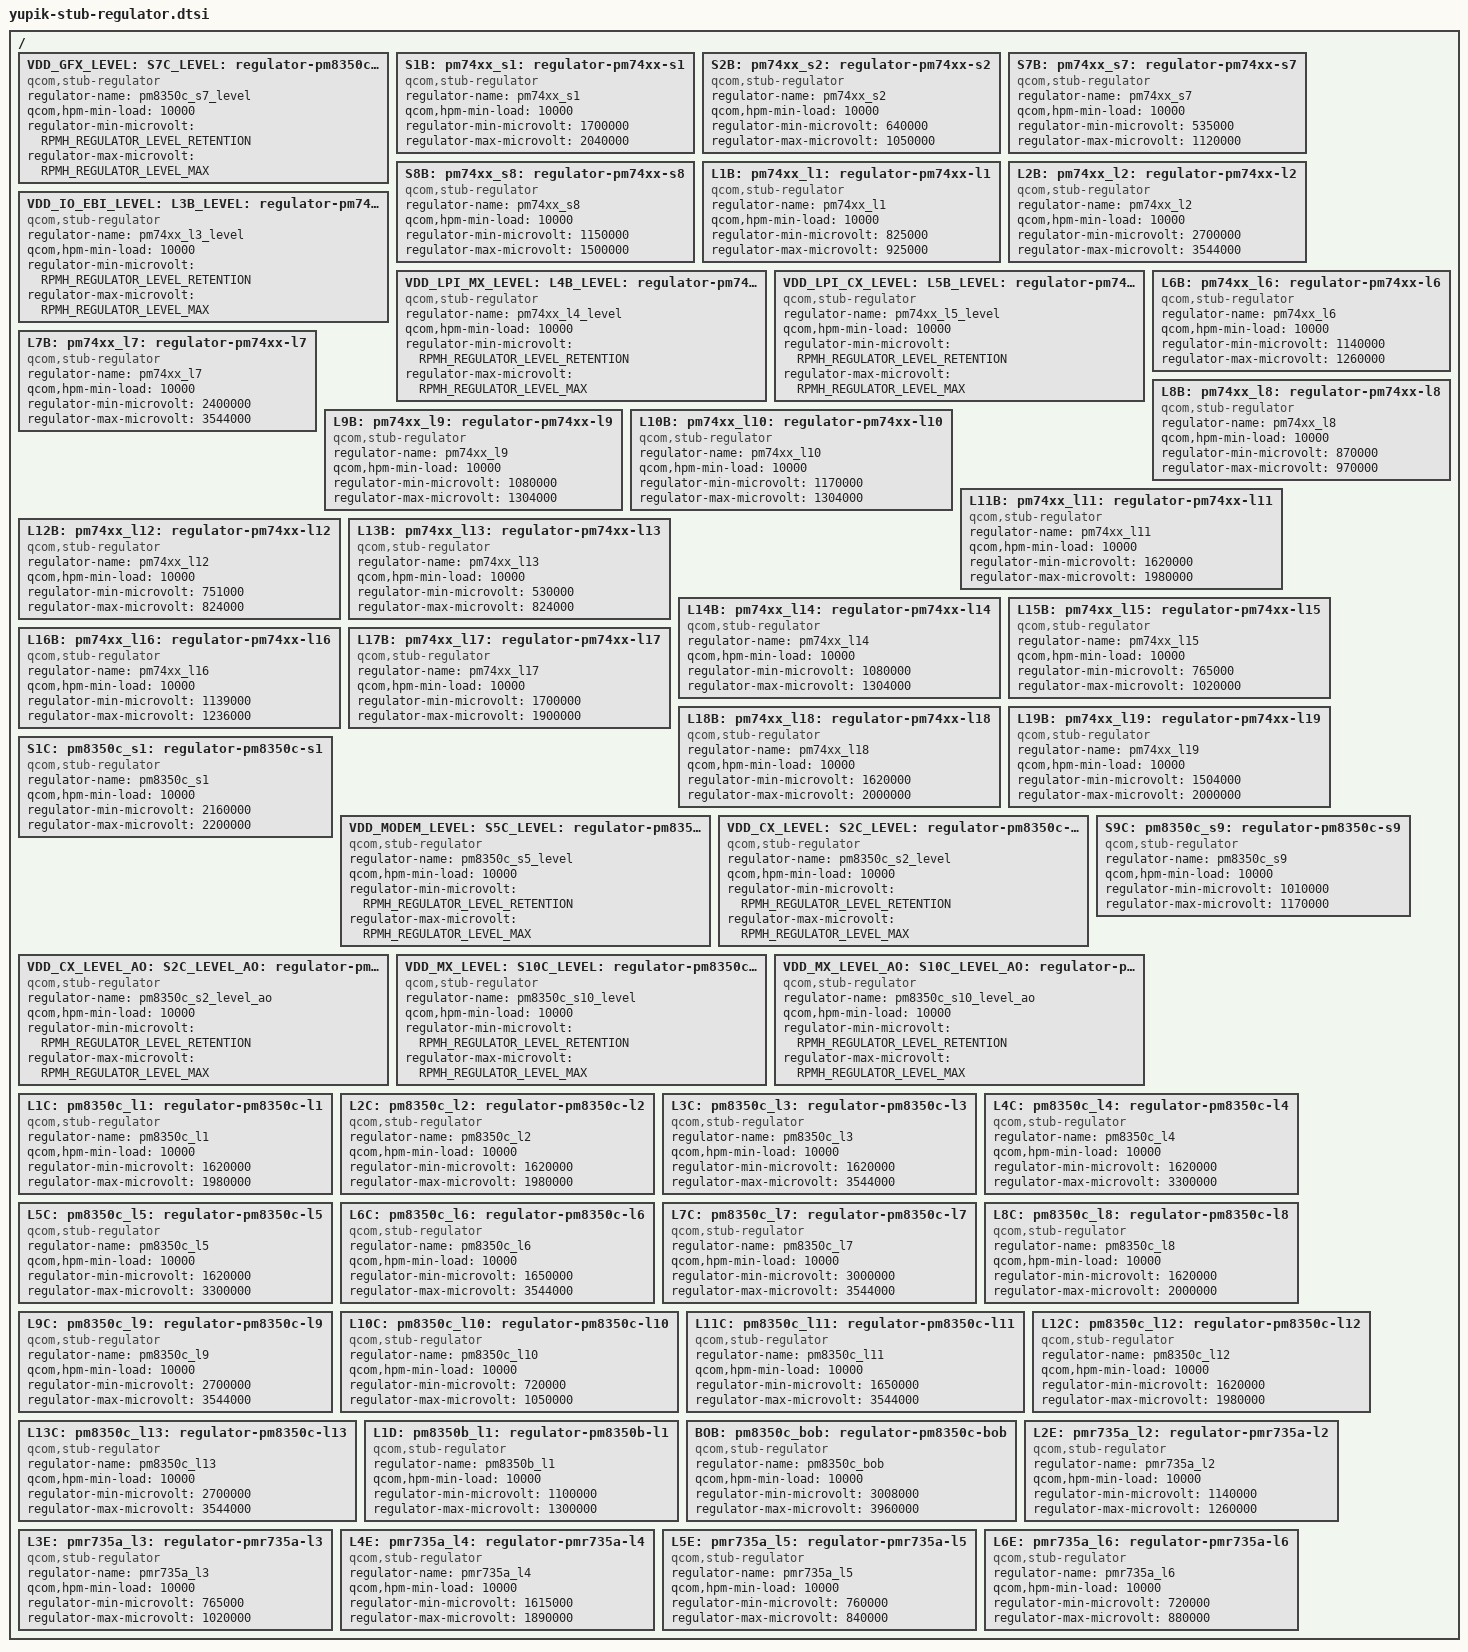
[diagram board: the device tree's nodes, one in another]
#include <dt-bindings/regulator/qcom,rpmh-regulator-levels.h>

/ {
	VDD_GFX_LEVEL:
	S7C_LEVEL:
	pm8350c_s7_level: regulator-pm8350c-s7-level {
		compatible = "qcom,stub-regulator";
		regulator-name = "pm8350c_s7_level";
		qcom,hpm-min-load = <10000>;
		regulator-min-microvolt = <RPMH_REGULATOR_LEVEL_RETENTION>;
		regulator-max-microvolt = <RPMH_REGULATOR_LEVEL_MAX>;
	};

	S1B:
	pm74xx_s1: regulator-pm74xx-s1 {
		compatible = "qcom,stub-regulator";
		regulator-name = "pm74xx_s1";
		qcom,hpm-min-load = <10000>;
		regulator-min-microvolt = <1700000>;
		regulator-max-microvolt = <2040000>;
	};

	S2B:
	pm74xx_s2: regulator-pm74xx-s2 {
		compatible = "qcom,stub-regulator";
		regulator-name = "pm74xx_s2";
		qcom,hpm-min-load = <10000>;
		regulator-min-microvolt = <640000>;
		regulator-max-microvolt = <1050000>;
	};

	S7B:
	pm74xx_s7: regulator-pm74xx-s7 {
		compatible = "qcom,stub-regulator";
		regulator-name = "pm74xx_s7";
		qcom,hpm-min-load = <10000>;
		regulator-min-microvolt = <535000>;
		regulator-max-microvolt = <1120000>;
	};

	S8B:
	pm74xx_s8: regulator-pm74xx-s8 {
		compatible = "qcom,stub-regulator";
		regulator-name = "pm74xx_s8";
		qcom,hpm-min-load = <10000>;
		regulator-min-microvolt = <1150000>;
		regulator-max-microvolt = <1500000>;
	};

	L1B:
	pm74xx_l1: regulator-pm74xx-l1 {
		compatible = "qcom,stub-regulator";
		regulator-name = "pm74xx_l1";
		qcom,hpm-min-load = <10000>;
		regulator-min-microvolt = <825000>;
		regulator-max-microvolt = <925000>;
	};

	L2B:
	pm74xx_l2: regulator-pm74xx-l2 {
		compatible = "qcom,stub-regulator";
		regulator-name = "pm74xx_l2";
		qcom,hpm-min-load = <10000>;
		regulator-min-microvolt = <2700000>;
		regulator-max-microvolt = <3544000>;
	};

	VDD_IO_EBI_LEVEL:
	L3B_LEVEL:
	pm74xx_l3_level: regulator-pm74xx-l3-level {
		compatible = "qcom,stub-regulator";
		regulator-name = "pm74xx_l3_level";
		qcom,hpm-min-load = <10000>;
		regulator-min-microvolt = <RPMH_REGULATOR_LEVEL_RETENTION>;
		regulator-max-microvolt = <RPMH_REGULATOR_LEVEL_MAX>;
	};

	VDD_LPI_MX_LEVEL:
	L4B_LEVEL:
	pm74xx_l4_level: regulator-pm74xx-l4-level {
		compatible = "qcom,stub-regulator";
		regulator-name = "pm74xx_l4_level";
		qcom,hpm-min-load = <10000>;
		regulator-min-microvolt = <RPMH_REGULATOR_LEVEL_RETENTION>;
		regulator-max-microvolt = <RPMH_REGULATOR_LEVEL_MAX>;
	};

	VDD_LPI_CX_LEVEL:
	L5B_LEVEL:
	pm74xx_l5_level: regulator-pm74xx-l5-level {
		compatible = "qcom,stub-regulator";
		regulator-name = "pm74xx_l5_level";
		qcom,hpm-min-load = <10000>;
		regulator-min-microvolt = <RPMH_REGULATOR_LEVEL_RETENTION>;
		regulator-max-microvolt = <RPMH_REGULATOR_LEVEL_MAX>;
	};

	L6B:
	pm74xx_l6: regulator-pm74xx-l6 {
		compatible = "qcom,stub-regulator";
		regulator-name = "pm74xx_l6";
		qcom,hpm-min-load = <10000>;
		regulator-min-microvolt = <1140000>;
		regulator-max-microvolt = <1260000>;
	};

	L7B:
	pm74xx_l7: regulator-pm74xx-l7 {
		compatible = "qcom,stub-regulator";
		regulator-name = "pm74xx_l7";
		qcom,hpm-min-load = <10000>;
		regulator-min-microvolt = <2400000>;
		regulator-max-microvolt = <3544000>;
	};

	L8B:
	pm74xx_l8: regulator-pm74xx-l8 {
		compatible = "qcom,stub-regulator";
		regulator-name = "pm74xx_l8";
		qcom,hpm-min-load = <10000>;
		regulator-min-microvolt = <870000>;
		regulator-max-microvolt = <970000>;
	};

	L9B:
	pm74xx_l9: regulator-pm74xx-l9 {
		compatible = "qcom,stub-regulator";
		regulator-name = "pm74xx_l9";
		qcom,hpm-min-load = <10000>;
		regulator-min-microvolt = <1080000>;
		regulator-max-microvolt = <1304000>;
	};

	L10B:
	pm74xx_l10: regulator-pm74xx-l10 {
		compatible = "qcom,stub-regulator";
		regulator-name = "pm74xx_l10";
		qcom,hpm-min-load = <10000>;
		regulator-min-microvolt = <1170000>;
		regulator-max-microvolt = <1304000>;
	};

	L11B:
	pm74xx_l11: regulator-pm74xx-l11 {
		compatible = "qcom,stub-regulator";
		regulator-name = "pm74xx_l11";
		qcom,hpm-min-load = <10000>;
		regulator-min-microvolt = <1620000>;
		regulator-max-microvolt = <1980000>;
	};

	L12B:
	pm74xx_l12: regulator-pm74xx-l12 {
		compatible = "qcom,stub-regulator";
		regulator-name = "pm74xx_l12";
		qcom,hpm-min-load = <10000>;
		regulator-min-microvolt = <751000>;
		regulator-max-microvolt = <824000>;
	};

	L13B:
	pm74xx_l13: regulator-pm74xx-l13 {
		compatible = "qcom,stub-regulator";
		regulator-name = "pm74xx_l13";
		qcom,hpm-min-load = <10000>;
		regulator-min-microvolt = <530000>;
		regulator-max-microvolt = <824000>;
	};

	L14B:
	pm74xx_l14: regulator-pm74xx-l14 {
		compatible = "qcom,stub-regulator";
		regulator-name = "pm74xx_l14";
		qcom,hpm-min-load = <10000>;
		regulator-min-microvolt = <1080000>;
		regulator-max-microvolt = <1304000>;
	};

	L15B:
	pm74xx_l15: regulator-pm74xx-l15 {
		compatible = "qcom,stub-regulator";
		regulator-name = "pm74xx_l15";
		qcom,hpm-min-load = <10000>;
		regulator-min-microvolt = <765000>;
		regulator-max-microvolt = <1020000>;
	};

	L16B:
	pm74xx_l16: regulator-pm74xx-l16 {
		compatible = "qcom,stub-regulator";
		regulator-name = "pm74xx_l16";
		qcom,hpm-min-load = <10000>;
		regulator-min-microvolt = <1139000>;
		regulator-max-microvolt = <1236000>;
	};

	L17B:
	pm74xx_l17: regulator-pm74xx-l17 {
		compatible = "qcom,stub-regulator";
		regulator-name = "pm74xx_l17";
		qcom,hpm-min-load = <10000>;
		regulator-min-microvolt = <1700000>;
		regulator-max-microvolt = <1900000>;
	};

	L18B:
	pm74xx_l18: regulator-pm74xx-l18 {
		compatible = "qcom,stub-regulator";
		regulator-name = "pm74xx_l18";
		qcom,hpm-min-load = <10000>;
		regulator-min-microvolt = <1620000>;
		regulator-max-microvolt = <2000000>;
	};

	L19B:
	pm74xx_l19: regulator-pm74xx-l19 {
		compatible = "qcom,stub-regulator";
		regulator-name = "pm74xx_l19";
		qcom,hpm-min-load = <10000>;
		regulator-min-microvolt = <1504000>;
		regulator-max-microvolt = <2000000>;
	};

	S1C:
	pm8350c_s1: regulator-pm8350c-s1 {
		compatible = "qcom,stub-regulator";
		regulator-name = "pm8350c_s1";
		qcom,hpm-min-load = <10000>;
		regulator-min-microvolt = <2160000>;
		regulator-max-microvolt = <2200000>;
	};

	VDD_MODEM_LEVEL:
	S5C_LEVEL:
	pm8350c_s5_level: regulator-pm8350c-s5-level {
		compatible = "qcom,stub-regulator";
		regulator-name = "pm8350c_s5_level";
		qcom,hpm-min-load = <10000>;
		regulator-min-microvolt = <RPMH_REGULATOR_LEVEL_RETENTION>;
		regulator-max-microvolt = <RPMH_REGULATOR_LEVEL_MAX>;
	};

	VDD_CX_LEVEL:
	S2C_LEVEL:
	pm8350c_s2_level: regulator-pm8350c-s2-level {
		compatible = "qcom,stub-regulator";
		regulator-name = "pm8350c_s2_level";
		qcom,hpm-min-load = <10000>;
		regulator-min-microvolt = <RPMH_REGULATOR_LEVEL_RETENTION>;
		regulator-max-microvolt = <RPMH_REGULATOR_LEVEL_MAX>;
	};

	VDD_CX_LEVEL_AO:
	S2C_LEVEL_AO:
	pm8350c_s2_level_ao: regulator-pm8350c-s2-level-ao {
		compatible = "qcom,stub-regulator";
		regulator-name = "pm8350c_s2_level_ao";
		qcom,hpm-min-load = <10000>;
		regulator-min-microvolt = <RPMH_REGULATOR_LEVEL_RETENTION>;
		regulator-max-microvolt = <RPMH_REGULATOR_LEVEL_MAX>;
	};

	S9C:
	pm8350c_s9: regulator-pm8350c-s9 {
		compatible = "qcom,stub-regulator";
		regulator-name = "pm8350c_s9";
		qcom,hpm-min-load = <10000>;
		regulator-min-microvolt = <1010000>;
		regulator-max-microvolt = <1170000>;
	};

	VDD_MX_LEVEL:
	S10C_LEVEL:
	pm8350c_s10_level: regulator-pm8350c-s10-level {
		compatible = "qcom,stub-regulator";
		regulator-name = "pm8350c_s10_level";
		qcom,hpm-min-load = <10000>;
		regulator-min-microvolt = <RPMH_REGULATOR_LEVEL_RETENTION>;
		regulator-max-microvolt = <RPMH_REGULATOR_LEVEL_MAX>;
	};

	VDD_MX_LEVEL_AO:
	S10C_LEVEL_AO:
	pm8350c_s10_level_ao: regulator-pm8350c-s10-level-ao {
		compatible = "qcom,stub-regulator";
		regulator-name = "pm8350c_s10_level_ao";
		qcom,hpm-min-load = <10000>;
		regulator-min-microvolt = <RPMH_REGULATOR_LEVEL_RETENTION>;
		regulator-max-microvolt = <RPMH_REGULATOR_LEVEL_MAX>;
	};

	L1C:
	pm8350c_l1: regulator-pm8350c-l1 {
		compatible = "qcom,stub-regulator";
		regulator-name = "pm8350c_l1";
		qcom,hpm-min-load = <10000>;
		regulator-min-microvolt = <1620000>;
		regulator-max-microvolt = <1980000>;
	};

	L2C:
	pm8350c_l2: regulator-pm8350c-l2 {
		compatible = "qcom,stub-regulator";
		regulator-name = "pm8350c_l2";
		qcom,hpm-min-load = <10000>;
		regulator-min-microvolt = <1620000>;
		regulator-max-microvolt = <1980000>;
	};

	L3C:
	pm8350c_l3: regulator-pm8350c-l3 {
		compatible = "qcom,stub-regulator";
		regulator-name = "pm8350c_l3";
		qcom,hpm-min-load = <10000>;
		regulator-min-microvolt = <1620000>;
		regulator-max-microvolt = <3544000>;
	};

	L4C:
	pm8350c_l4: regulator-pm8350c-l4 {
		compatible = "qcom,stub-regulator";
		regulator-name = "pm8350c_l4";
		qcom,hpm-min-load = <10000>;
		regulator-min-microvolt = <1620000>;
		regulator-max-microvolt = <3300000>;
	};

	L5C:
	pm8350c_l5: regulator-pm8350c-l5 {
		compatible = "qcom,stub-regulator";
		regulator-name = "pm8350c_l5";
		qcom,hpm-min-load = <10000>;
		regulator-min-microvolt = <1620000>;
		regulator-max-microvolt = <3300000>;
	};

	L6C:
	pm8350c_l6: regulator-pm8350c-l6 {
		compatible = "qcom,stub-regulator";
		regulator-name = "pm8350c_l6";
		qcom,hpm-min-load = <10000>;
		regulator-min-microvolt = <1650000>;
		regulator-max-microvolt = <3544000>;
	};

	L7C:
	pm8350c_l7: regulator-pm8350c-l7 {
		compatible = "qcom,stub-regulator";
		regulator-name = "pm8350c_l7";
		qcom,hpm-min-load = <10000>;
		regulator-min-microvolt = <3000000>;
		regulator-max-microvolt = <3544000>;
	};

	L8C:
	pm8350c_l8: regulator-pm8350c-l8 {
		compatible = "qcom,stub-regulator";
		regulator-name = "pm8350c_l8";
		qcom,hpm-min-load = <10000>;
		regulator-min-microvolt = <1620000>;
		regulator-max-microvolt = <2000000>;
	};

	L9C:
	pm8350c_l9: regulator-pm8350c-l9 {
		compatible = "qcom,stub-regulator";
		regulator-name = "pm8350c_l9";
		qcom,hpm-min-load = <10000>;
		regulator-min-microvolt = <2700000>;
		regulator-max-microvolt = <3544000>;
	};

	L10C:
	pm8350c_l10: regulator-pm8350c-l10 {
		compatible = "qcom,stub-regulator";
		regulator-name = "pm8350c_l10";
		qcom,hpm-min-load = <10000>;
		regulator-min-microvolt = <720000>;
		regulator-max-microvolt = <1050000>;
	};

	L11C:
	pm8350c_l11: regulator-pm8350c-l11 {
		compatible = "qcom,stub-regulator";
		regulator-name = "pm8350c_l11";
		qcom,hpm-min-load = <10000>;
		regulator-min-microvolt = <1650000>;
		regulator-max-microvolt = <3544000>;
	};

	L12C:
	pm8350c_l12: regulator-pm8350c-l12 {
		compatible = "qcom,stub-regulator";
		regulator-name = "pm8350c_l12";
		qcom,hpm-min-load = <10000>;
		regulator-min-microvolt = <1620000>;
		regulator-max-microvolt = <1980000>;
	};

	L13C:
	pm8350c_l13: regulator-pm8350c-l13 {
		compatible = "qcom,stub-regulator";
		regulator-name = "pm8350c_l13";
		qcom,hpm-min-load = <10000>;
		regulator-min-microvolt = <2700000>;
		regulator-max-microvolt = <3544000>;
	};

	L1D:
	pm8350b_l1: regulator-pm8350b-l1 {
		compatible = "qcom,stub-regulator";
		regulator-name = "pm8350b_l1";
		qcom,hpm-min-load = <10000>;
		regulator-min-microvolt = <1100000>;
		regulator-max-microvolt = <1300000>;
	};

	BOB:
	pm8350c_bob: regulator-pm8350c-bob {
		compatible = "qcom,stub-regulator";
		regulator-name = "pm8350c_bob";
		qcom,hpm-min-load = <10000>;
		regulator-min-microvolt = <3008000>;
		regulator-max-microvolt = <3960000>;
	};

	L2E:
	pmr735a_l2: regulator-pmr735a-l2 {
		compatible = "qcom,stub-regulator";
		regulator-name = "pmr735a_l2";
		qcom,hpm-min-load = <10000>;
		regulator-min-microvolt = <1140000>;
		regulator-max-microvolt = <1260000>;
	};

	L3E:
	pmr735a_l3: regulator-pmr735a-l3 {
		compatible = "qcom,stub-regulator";
		regulator-name = "pmr735a_l3";
		qcom,hpm-min-load = <10000>;
		regulator-min-microvolt = <765000>;
		regulator-max-microvolt = <1020000>;
	};

	L4E:
	pmr735a_l4: regulator-pmr735a-l4 {
		compatible = "qcom,stub-regulator";
		regulator-name = "pmr735a_l4";
		qcom,hpm-min-load = <10000>;
		regulator-min-microvolt = <1615000>;
		regulator-max-microvolt = <1890000>;
	};

	L5E:
	pmr735a_l5: regulator-pmr735a-l5 {
		compatible = "qcom,stub-regulator";
		regulator-name = "pmr735a_l5";
		qcom,hpm-min-load = <10000>;
		regulator-min-microvolt = <760000>;
		regulator-max-microvolt = <840000>;
	};

	L6E:
	pmr735a_l6: regulator-pmr735a-l6 {
		compatible = "qcom,stub-regulator";
		regulator-name = "pmr735a_l6";
		qcom,hpm-min-load = <10000>;
		regulator-min-microvolt = <720000>;
		regulator-max-microvolt = <880000>;
	};
};
